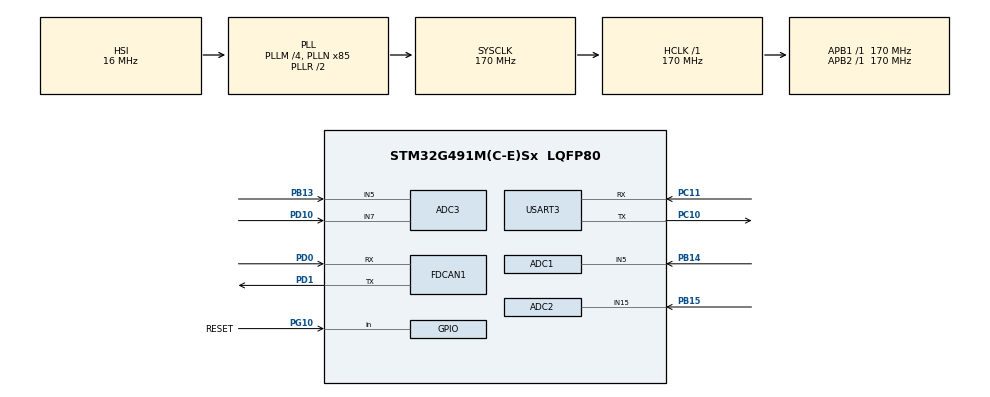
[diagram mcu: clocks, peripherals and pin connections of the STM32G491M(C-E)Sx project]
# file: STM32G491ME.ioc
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ADC1.Channel-0\#ChannelRegularConversion=ADC_CHANNEL_5
ADC1.NbrOfConversionFlag=1
ADC1.OffsetNumber-0\#ChannelRegularConversion=ADC_OFFSET_NONE
ADC1.Rank-0\#ChannelRegularConversion=1
ADC1.SamplingTime-0\#ChannelRegularConversion=ADC_SAMPLETIME_640CYCLES_5
ADC1.master=1
ADC2.Channel-0\#ChannelRegularConversion=ADC_CHANNEL_15
ADC2.NbrOfConversionFlag=1
ADC2.OffsetNumber-0\#ChannelRegularConversion=ADC_OFFSET_NONE
ADC2.Rank-0\#ChannelRegularConversion=1
ADC2.SamplingTime-0\#ChannelRegularConversion=ADC_SAMPLETIME_640CYCLES_5
ADC3.Channel-3\#ChannelRegularConversion=ADC_CHANNEL_7
ADC3.Channel-4\#ChannelRegularConversion=ADC_CHANNEL_5
ADC3.EnableInjectedConversion=DISABLE
ADC3.NbrOfConversion=2
ADC3.NbrOfConversionFlag=1
ADC3.OffsetNumber-3\#ChannelRegularConversion=ADC_OFFSET_NONE
ADC3.OffsetNumber-4\#ChannelRegularConversion=ADC_OFFSET_NONE
ADC3.Rank-3\#ChannelRegularConversion=1
ADC3.Rank-4\#ChannelRegularConversion=2
ADC3.SamplingTime-3\#ChannelRegularConversion=ADC_SAMPLETIME_640CYCLES_5
ADC3.SamplingTime-4\#ChannelRegularConversion=ADC_SAMPLETIME_640CYCLES_5
ADC3.master=1
FDCAN1.AutoRetransmission=ENABLE
FDCAN1.CalculateBaudRateNominal=999999
FDCAN1.CalculateTimeBitNominal=1000
FDCAN1.CalculateTimeQuantumNominal=5.882352941176471
FDCAN1.DataPrescaler=5
FDCAN1.DataSyncJumpWidth=13
FDCAN1.DataTimeSeg1=3
FDCAN1.DataTimeSeg2=3
FDCAN1.FrameFormat=FDCAN_FRAME_FD_BRS
FDCAN1.NominalPrescaler=1
FDCAN1.NominalSyncJumpWidth=5
FDCAN1.NominalTimeSeg1=164
FDCAN1.NominalTimeSeg2=5
FREERTOS.Tasks01=defaultTask,0,192,StartDefaultTask,Default,NULL,Dynamic,NULL,NULL
FREERTOS.configMINIMAL_STACK_SIZE=192
FREERTOS.configTOTAL_HEAP_SIZE=65536
FREERTOS.configUSE_NEWLIB_REENTRANT=1
FREERTOS.configUSE_TIMERS=1
Mcu.Family=STM32G4
Mcu.Name=STM32G491M(C-E)Sx
Mcu.Package=LQFP80
NVIC.FDCAN1_IT0_IRQn=true\:5\:0\:false\:false\:true\:true\:true\:true\:true
NVIC.PriorityGroup=NVIC_PRIORITYGROUP_4
NVIC.TIM2_IRQn=true\:15\:0\:false\:false\:true\:false\:false\:true\:true
NVIC.TimeBase=TIM2_IRQn
NVIC.TimeBaseIP=TIM2
NVIC.USART3_IRQn=true\:5\:0\:true\:false\:true\:true\:true\:true\:true
PA13.Mode=Trace_Asynchronous_SW
PA13.Signal=SYS_JTMS-SWDIO
PA14.Mode=Trace_Asynchronous_SW
PA14.Signal=SYS_JTCK-SWCLK
PB13.Mode=IN5-Single-Ended
PB13.Signal=ADC3_IN5
PB14.Mode=IN5-Single-Ended
PB14.Signal=ADC1_IN5
PB15.Mode=IN15-Single-Ended
PB15.Signal=ADC2_IN15
PB3.Mode=Trace_Asynchronous_SW
PB3.Signal=SYS_JTDO-SWO
PC10.Mode=Asynchronous
PC10.Signal=USART3_TX
PC11.Mode=Asynchronous
PC11.Signal=USART3_RX
PD0.Mode=FDCAN_Activate
PD0.Signal=FDCAN1_RX
PD1.Mode=FDCAN_Activate
PD1.Signal=FDCAN1_TX
PD10.Mode=IN7-Single-Ended
PD10.Signal=ADC3_IN7
PG10-NRST.GPIO_Label=RESET
PG10-NRST.Signal=GPIO_Input
ProjectManager.HeapSize=0x200
ProjectManager.StackSize=0x400
ProjectManager.TargetToolchain=STM32CubeIDE
RCC.ADC12Freq_Value=170000000
RCC.ADC345Freq_Value=170000000
RCC.AHBFreq_Value=170000000
RCC.APB1Freq_Value=170000000
RCC.APB1TimFreq_Value=170000000
RCC.APB2Freq_Value=170000000
RCC.APB2TimFreq_Value=170000000
RCC.CortexFreq_Value=170000000
RCC.EXTERNAL_CLOCK_VALUE=12288000
RCC.HCLKFreq_Value=170000000
RCC.HSE_VALUE=32000000
RCC.HSI48_VALUE=48000000
RCC.HSI_VALUE=16000000
RCC.LSE_VALUE=32768
RCC.PLLM=RCC_PLLM_DIV4
RCC.PLLN=85
RCC.SYSCLKFreq_VALUE=170000000
RCC.SYSCLKSource=RCC_SYSCLKSOURCE_PLLCLK
RCC.VCOOutputFreq_Value=340000000
USART3.VirtualMode-Asynchronous=VM_ASYNC
VP_CRC_VS_CRC.Mode=CRC_Activate
VP_FREERTOS_VS_CMSIS_V1.Mode=CMSIS_V1
VP_SYS_VS_DBSignals.Mode=DisableDeadBatterySignals
VP_SYS_VS_tim2.Mode=TIM2
board=custom

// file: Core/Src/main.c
/* USER CODE BEGIN Header */
/**
  ******************************************************************************
  * @file           : main.c
  * @brief          : Main program body
  ******************************************************************************
  * @attention
  *
  * Copyright (c) 2026 STMicroelectronics.
  * All rights reserved.
  *
  * This software is licensed under terms that can be found in the LICENSE file
  * in the root directory of this software component.
  * If no LICENSE file comes with this software, it is provided AS-IS.
  *
  ******************************************************************************
  */
/* USER CODE END Header */
#include "main.h"
#include "cmsis_os.h"

/* USER CODE BEGIN Includes */
#include "RunInterface.hpp"
//#define USE_FULL_LL_DRIVER
/* USER CODE END Includes */

ADC_HandleTypeDef hadc1;
ADC_HandleTypeDef hadc2;
ADC_HandleTypeDef hadc3;

CRC_HandleTypeDef hcrc;

FDCAN_HandleTypeDef hfdcan1;

osThreadId defaultTaskHandle;

void SystemClock_Config(void);
static void MX_GPIO_Init(void);
static void MX_CRC_Init(void);
static void MX_USART3_UART_Init(void);
static void MX_FDCAN1_Init(void);
static void MX_ADC3_Init(void);
static void MX_ADC1_Init(void);
static void MX_ADC2_Init(void);
void StartDefaultTask(void const * argument);

int main(void)
{

  /* MCU Configuration--------------------------------------------------------*/

  /* Reset of all peripherals, Initializes the Flash interface and the Systick. */
  HAL_Init();

  /* Configure the system clock */
  SystemClock_Config();

  /* Initialize all configured peripherals */
  MX_GPIO_Init();
  MX_CRC_Init();
  MX_USART3_UART_Init();
  MX_FDCAN1_Init();
  MX_ADC3_Init();
  MX_ADC1_Init();
  MX_ADC2_Init();

  /* Create the thread(s) */
  /* definition and creation of defaultTask */
  osThreadDef(defaultTask, StartDefaultTask, osPriorityNormal, 0, 192);
  defaultTaskHandle = osThreadCreate(osThread(defaultTask), NULL);

  /* USER CODE BEGIN RTOS_THREADS */
  /* add threads, ... */
  run_interface();
  /* USER CODE END RTOS_THREADS */

  /* Start scheduler */
  osKernelStart();

  /* We should never get here as control is now taken by the scheduler */

  /* Infinite loop */
  while (1)
  {

  }
}

void SystemClock_Config(void)
{
  RCC_OscInitTypeDef RCC_OscInitStruct = {0};
  RCC_ClkInitTypeDef RCC_ClkInitStruct = {0};

  /** Configure the main internal regulator output voltage
  */
  HAL_PWREx_ControlVoltageScaling(PWR_REGULATOR_VOLTAGE_SCALE1_BOOST);

  /** Initializes the RCC Oscillators according to the specified parameters
  * in the RCC_OscInitTypeDef structure.
  */
  RCC_OscInitStruct.OscillatorType = RCC_OSCILLATORTYPE_HSI;
  RCC_OscInitStruct.HSIState = RCC_HSI_ON;
  RCC_OscInitStruct.HSICalibrationValue = RCC_HSICALIBRATION_DEFAULT;
  RCC_OscInitStruct.PLL.PLLState = RCC_PLL_ON;
  RCC_OscInitStruct.PLL.PLLSource = RCC_PLLSOURCE_HSI;
  RCC_OscInitStruct.PLL.PLLM = RCC_PLLM_DIV4;
  RCC_OscInitStruct.PLL.PLLN = 85;
  RCC_OscInitStruct.PLL.PLLP = RCC_PLLP_DIV2;
  RCC_OscInitStruct.PLL.PLLQ = RCC_PLLQ_DIV2;
  RCC_OscInitStruct.PLL.PLLR = RCC_PLLR_DIV2;
  if (HAL_RCC_OscConfig(&RCC_OscInitStruct) != HAL_OK)
  {
    Error_Handler();
  }

  /** Initializes the CPU, AHB and APB buses clocks
  */
  RCC_ClkInitStruct.ClockType = RCC_CLOCKTYPE_HCLK|RCC_CLOCKTYPE_SYSCLK
                              |RCC_CLOCKTYPE_PCLK1|RCC_CLOCKTYPE_PCLK2;
  RCC_ClkInitStruct.SYSCLKSource = RCC_SYSCLKSOURCE_PLLCLK;
  RCC_ClkInitStruct.AHBCLKDivider = RCC_SYSCLK_DIV1;
  RCC_ClkInitStruct.APB1CLKDivider = RCC_HCLK_DIV1;
  RCC_ClkInitStruct.APB2CLKDivider = RCC_HCLK_DIV1;

  if (HAL_RCC_ClockConfig(&RCC_ClkInitStruct, FLASH_LATENCY_4) != HAL_OK)
  {
    Error_Handler();
  }
}

static void MX_ADC1_Init(void)
{

  ADC_MultiModeTypeDef multimode = {0};
  ADC_ChannelConfTypeDef sConfig = {0};

  /** Common config
  */
  hadc1.Instance = ADC1;
  hadc1.Init.ClockPrescaler = ADC_CLOCK_SYNC_PCLK_DIV4;
  hadc1.Init.Resolution = ADC_RESOLUTION_12B;
  hadc1.Init.DataAlign = ADC_DATAALIGN_RIGHT;
  hadc1.Init.GainCompensation = 0;
  hadc1.Init.ScanConvMode = ADC_SCAN_DISABLE;
  hadc1.Init.EOCSelection = ADC_EOC_SINGLE_CONV;
  hadc1.Init.LowPowerAutoWait = DISABLE;
  hadc1.Init.ContinuousConvMode = DISABLE;
  hadc1.Init.NbrOfConversion = 1;
  hadc1.Init.DiscontinuousConvMode = DISABLE;
  hadc1.Init.ExternalTrigConv = ADC_SOFTWARE_START;
  hadc1.Init.ExternalTrigConvEdge = ADC_EXTERNALTRIGCONVEDGE_NONE;
  hadc1.Init.DMAContinuousRequests = DISABLE;
  hadc1.Init.Overrun = ADC_OVR_DATA_PRESERVED;
  hadc1.Init.OversamplingMode = DISABLE;
  if (HAL_ADC_Init(&hadc1) != HAL_OK)
  {
    Error_Handler();
  }

  /** Configure the ADC multi-mode
  */
  multimode.Mode = ADC_MODE_INDEPENDENT;
  if (HAL_ADCEx_MultiModeConfigChannel(&hadc1, &multimode) != HAL_OK)
  {
    Error_Handler();
  }

  /** Configure Regular Channel
  */
  sConfig.Channel = ADC_CHANNEL_5;
  sConfig.Rank = ADC_REGULAR_RANK_1;
  sConfig.SamplingTime = ADC_SAMPLETIME_640CYCLES_5;
  sConfig.SingleDiff = ADC_SINGLE_ENDED;
  sConfig.OffsetNumber = ADC_OFFSET_NONE;
  sConfig.Offset = 0;
  if (HAL_ADC_ConfigChannel(&hadc1, &sConfig) != HAL_OK)
  {
    Error_Handler();
  }

}

static void MX_ADC2_Init(void)
{

  ADC_ChannelConfTypeDef sConfig = {0};

  /** Common config
  */
  hadc2.Instance = ADC2;
  hadc2.Init.ClockPrescaler = ADC_CLOCK_SYNC_PCLK_DIV4;
  hadc2.Init.Resolution = ADC_RESOLUTION_12B;
  hadc2.Init.DataAlign = ADC_DATAALIGN_RIGHT;
  hadc2.Init.GainCompensation = 0;
  hadc2.Init.ScanConvMode = ADC_SCAN_DISABLE;
  hadc2.Init.EOCSelection = ADC_EOC_SINGLE_CONV;
  hadc2.Init.LowPowerAutoWait = DISABLE;
  hadc2.Init.ContinuousConvMode = DISABLE;
  hadc2.Init.NbrOfConversion = 1;
  hadc2.Init.DiscontinuousConvMode = DISABLE;
  hadc2.Init.ExternalTrigConv = ADC_SOFTWARE_START;
  hadc2.Init.ExternalTrigConvEdge = ADC_EXTERNALTRIGCONVEDGE_NONE;
  hadc2.Init.DMAContinuousRequests = DISABLE;
  hadc2.Init.Overrun = ADC_OVR_DATA_PRESERVED;
  hadc2.Init.OversamplingMode = DISABLE;
  if (HAL_ADC_Init(&hadc2) != HAL_OK)
  {
    Error_Handler();
  }

  /** Configure Regular Channel
  */
  sConfig.Channel = ADC_CHANNEL_15;
  sConfig.Rank = ADC_REGULAR_RANK_1;
  sConfig.SamplingTime = ADC_SAMPLETIME_640CYCLES_5;
  sConfig.SingleDiff = ADC_SINGLE_ENDED;
  sConfig.OffsetNumber = ADC_OFFSET_NONE;
  sConfig.Offset = 0;
  if (HAL_ADC_ConfigChannel(&hadc2, &sConfig) != HAL_OK)
  {
    Error_Handler();
  }

}

static void MX_ADC3_Init(void)
{

  ADC_ChannelConfTypeDef sConfig = {0};

  /** Common config
  */
  hadc3.Instance = ADC3;
  hadc3.Init.ClockPrescaler = ADC_CLOCK_SYNC_PCLK_DIV4;
  hadc3.Init.Resolution = ADC_RESOLUTION_12B;
  hadc3.Init.DataAlign = ADC_DATAALIGN_RIGHT;
  hadc3.Init.GainCompensation = 0;
  hadc3.Init.ScanConvMode = ADC_SCAN_ENABLE;
  hadc3.Init.EOCSelection = ADC_EOC_SINGLE_CONV;
  hadc3.Init.LowPowerAutoWait = DISABLE;
  hadc3.Init.ContinuousConvMode = DISABLE;
  hadc3.Init.NbrOfConversion = 2;
  hadc3.Init.DiscontinuousConvMode = DISABLE;
  hadc3.Init.ExternalTrigConv = ADC_SOFTWARE_START;
  hadc3.Init.ExternalTrigConvEdge = ADC_EXTERNALTRIGCONVEDGE_NONE;
  hadc3.Init.DMAContinuousRequests = DISABLE;
  hadc3.Init.Overrun = ADC_OVR_DATA_PRESERVED;
  hadc3.Init.OversamplingMode = DISABLE;
  if (HAL_ADC_Init(&hadc3) != HAL_OK)
  {
    Error_Handler();
  }

  /** Configure Regular Channel
  */
  sConfig.Channel = ADC_CHANNEL_7;
  sConfig.Rank = ADC_REGULAR_RANK_1;
  sConfig.SamplingTime = ADC_SAMPLETIME_640CYCLES_5;
  sConfig.SingleDiff = ADC_SINGLE_ENDED;
  sConfig.OffsetNumber = ADC_OFFSET_NONE;
  sConfig.Offset = 0;
  if (HAL_ADC_ConfigChannel(&hadc3, &sConfig) != HAL_OK)
  {
    Error_Handler();
  }

  /** Configure Regular Channel
  */
  sConfig.Channel = ADC_CHANNEL_5;
  sConfig.Rank = ADC_REGULAR_RANK_2;
  if (HAL_ADC_ConfigChannel(&hadc3, &sConfig) != HAL_OK)
  {
    Error_Handler();
  }

}

static void MX_CRC_Init(void)
{

  hcrc.Instance = CRC;
  hcrc.Init.DefaultPolynomialUse = DEFAULT_POLYNOMIAL_ENABLE;
  hcrc.Init.DefaultInitValueUse = DEFAULT_INIT_VALUE_ENABLE;
  hcrc.Init.InputDataInversionMode = CRC_INPUTDATA_INVERSION_NONE;
  hcrc.Init.OutputDataInversionMode = CRC_OUTPUTDATA_INVERSION_DISABLE;
  hcrc.InputDataFormat = CRC_INPUTDATA_FORMAT_BYTES;
  if (HAL_CRC_Init(&hcrc) != HAL_OK)
  {
    Error_Handler();
  }

}

static void MX_FDCAN1_Init(void)
{

  hfdcan1.Instance = FDCAN1;
  hfdcan1.Init.ClockDivider = FDCAN_CLOCK_DIV1;
  hfdcan1.Init.FrameFormat = FDCAN_FRAME_FD_BRS;
  hfdcan1.Init.Mode = FDCAN_MODE_NORMAL;
  hfdcan1.Init.AutoRetransmission = ENABLE;
  hfdcan1.Init.TransmitPause = DISABLE;
  hfdcan1.Init.ProtocolException = DISABLE;
  hfdcan1.Init.NominalPrescaler = 1;
  hfdcan1.Init.NominalSyncJumpWidth = 5;
  hfdcan1.Init.NominalTimeSeg1 = 164;
  hfdcan1.Init.NominalTimeSeg2 = 5;
  hfdcan1.Init.DataPrescaler = 5;
  hfdcan1.Init.DataSyncJumpWidth = 13;
  hfdcan1.Init.DataTimeSeg1 = 3;
  hfdcan1.Init.DataTimeSeg2 = 3;
  hfdcan1.Init.StdFiltersNbr = 0;
  hfdcan1.Init.ExtFiltersNbr = 0;
  hfdcan1.Init.TxFifoQueueMode = FDCAN_TX_FIFO_OPERATION;
  if (HAL_FDCAN_Init(&hfdcan1) != HAL_OK)
  {
    Error_Handler();
  }

}

static void MX_USART3_UART_Init(void)
{

  LL_USART_InitTypeDef USART_InitStruct = {0};

  LL_GPIO_InitTypeDef GPIO_InitStruct = {0};
  RCC_PeriphCLKInitTypeDef PeriphClkInit = {0};

  /** Initializes the peripherals clocks
  */
  PeriphClkInit.PeriphClockSelection = RCC_PERIPHCLK_USART3;
  PeriphClkInit.Usart3ClockSelection = RCC_USART3CLKSOURCE_PCLK1;
  if (HAL_RCCEx_PeriphCLKConfig(&PeriphClkInit) != HAL_OK)
  {
    Error_Handler();
  }

  /* Peripheral clock enable */
  LL_APB1_GRP1_EnableClock(LL_APB1_GRP1_PERIPH_USART3);

  LL_AHB2_GRP1_EnableClock(LL_AHB2_GRP1_PERIPH_GPIOC);
  /**USART3 GPIO Configuration
  PC10   ------> USART3_TX
  PC11   ------> USART3_RX
  */
  GPIO_InitStruct.Pin = LL_GPIO_PIN_10;
  GPIO_InitStruct.Mode = LL_GPIO_MODE_ALTERNATE;
  GPIO_InitStruct.Speed = LL_GPIO_SPEED_FREQ_LOW;
  GPIO_InitStruct.OutputType = LL_GPIO_OUTPUT_PUSHPULL;
  GPIO_InitStruct.Pull = LL_GPIO_PULL_NO;
  GPIO_InitStruct.Alternate = LL_GPIO_AF_7;
  LL_GPIO_Init(GPIOC, &GPIO_InitStruct);

  GPIO_InitStruct.Pin = LL_GPIO_PIN_11;
  GPIO_InitStruct.Mode = LL_GPIO_MODE_ALTERNATE;
  GPIO_InitStruct.Speed = LL_GPIO_SPEED_FREQ_LOW;
  GPIO_InitStruct.OutputType = LL_GPIO_OUTPUT_PUSHPULL;
  GPIO_InitStruct.Pull = LL_GPIO_PULL_NO;
  GPIO_InitStruct.Alternate = LL_GPIO_AF_7;
  LL_GPIO_Init(GPIOC, &GPIO_InitStruct);

  /* USART3 interrupt Init */
  NVIC_SetPriority(USART3_IRQn, NVIC_EncodePriority(NVIC_GetPriorityGrouping(),5, 0));
  NVIC_EnableIRQ(USART3_IRQn);

  USART_InitStruct.PrescalerValue = LL_USART_PRESCALER_DIV1;
  USART_InitStruct.BaudRate = 115200;
  USART_InitStruct.DataWidth = LL_USART_DATAWIDTH_8B;
  USART_InitStruct.StopBits = LL_USART_STOPBITS_1;
  USART_InitStruct.Parity = LL_USART_PARITY_NONE;
  USART_InitStruct.TransferDirection = LL_USART_DIRECTION_TX_RX;
  USART_InitStruct.HardwareFlowControl = LL_USART_HWCONTROL_NONE;
  USART_InitStruct.OverSampling = LL_USART_OVERSAMPLING_16;
  LL_USART_Init(USART3, &USART_InitStruct);
  LL_USART_SetTXFIFOThreshold(USART3, LL_USART_FIFOTHRESHOLD_1_8);
  LL_USART_SetRXFIFOThreshold(USART3, LL_USART_FIFOTHRESHOLD_1_8);
  LL_USART_DisableFIFO(USART3);
  LL_USART_ConfigAsyncMode(USART3);

  LL_USART_Enable(USART3);

  /* Polling USART3 initialisation */
  while((!(LL_USART_IsActiveFlag_TEACK(USART3))) || (!(LL_USART_IsActiveFlag_REACK(USART3))))
  {
  }

}

static void MX_GPIO_Init(void)
{
  LL_GPIO_InitTypeDef GPIO_InitStruct = {0};

  /* GPIO Ports Clock Enable */
  LL_AHB2_GRP1_EnableClock(LL_AHB2_GRP1_PERIPH_GPIOG);
  LL_AHB2_GRP1_EnableClock(LL_AHB2_GRP1_PERIPH_GPIOB);
  LL_AHB2_GRP1_EnableClock(LL_AHB2_GRP1_PERIPH_GPIOD);
  LL_AHB2_GRP1_EnableClock(LL_AHB2_GRP1_PERIPH_GPIOA);
  LL_AHB2_GRP1_EnableClock(LL_AHB2_GRP1_PERIPH_GPIOC);

  /**/
  GPIO_InitStruct.Pin = RESET_Pin;
  GPIO_InitStruct.Mode = LL_GPIO_MODE_INPUT;
  GPIO_InitStruct.Pull = LL_GPIO_PULL_NO;
  LL_GPIO_Init(RESET_GPIO_Port, &GPIO_InitStruct);

}

void StartDefaultTask(void const * argument)
{
  for(;;)
  {
    osDelay(1);
  }
}

void HAL_TIM_PeriodElapsedCallback(TIM_HandleTypeDef *htim)
{
  if (htim->Instance == TIM2)
  {
    HAL_IncTick();
  }
}

void Error_Handler(void)
{
  __disable_irq();
  while (1)
  {
  }
}
